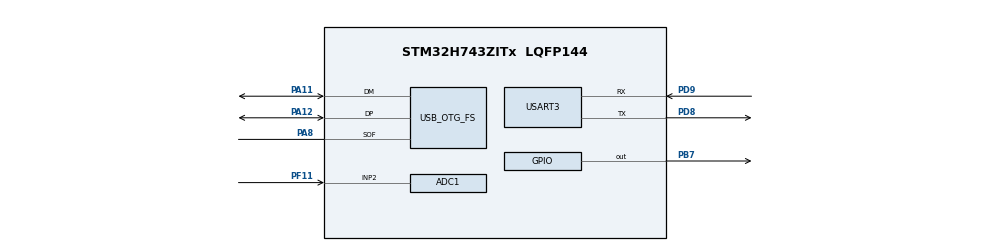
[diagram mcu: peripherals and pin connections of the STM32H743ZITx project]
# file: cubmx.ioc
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ADC1.Channel-0\#ChannelRegularConversion=ADC_CHANNEL_2
ADC1.NbrOfConversionFlag=1
ADC1.OffsetNumber-0\#ChannelRegularConversion=ADC_OFFSET_NONE
ADC1.Rank-0\#ChannelRegularConversion=1
ADC1.SamplingTime-0\#ChannelRegularConversion=ADC_SAMPLETIME_1CYCLE_5
ADC1.master=1
CORTEX_M7.CPU_DCache=Enabled
CORTEX_M7.CPU_ICache=Enabled
Dma.ADC1.0.Direction=DMA_PERIPH_TO_MEMORY
Dma.ADC1.0.EventEnable=DISABLE
Dma.ADC1.0.FIFOMode=DMA_FIFOMODE_ENABLE
Dma.ADC1.0.FIFOThreshold=DMA_FIFO_THRESHOLD_FULL
Dma.ADC1.0.Instance=DMA1_Stream0
Dma.ADC1.0.MemBurst=DMA_MBURST_SINGLE
Dma.ADC1.0.MemDataAlignment=DMA_MDATAALIGN_HALFWORD
Dma.ADC1.0.MemInc=DMA_MINC_ENABLE
Dma.ADC1.0.Mode=DMA_CIRCULAR
Dma.ADC1.0.PeriphBurst=DMA_PBURST_SINGLE
Dma.ADC1.0.PeriphDataAlignment=DMA_PDATAALIGN_HALFWORD
Dma.ADC1.0.PeriphInc=DMA_PINC_DISABLE
Dma.ADC1.0.Polarity=HAL_DMAMUX_REQ_GEN_RISING
Dma.ADC1.0.Priority=DMA_PRIORITY_LOW
Dma.ADC1.0.RequestNumber=1
Dma.ADC1.0.SyncEnable=ENABLE
Dma.ADC1.0.SyncPolarity=HAL_DMAMUX_SYNC_RISING
Dma.ADC1.0.SyncRequestNumber=1
Dma.Request0=ADC1
Mcu.Family=STM32H7
Mcu.Name=STM32H743ZITx
Mcu.Package=LQFP144
NVIC.DMA1_Stream0_IRQn=true\:0\:0\:false\:false\:true\:false
NVIC.DMAMUX1_OVR_IRQn=true\:0\:0\:false\:false\:true\:false
NVIC.OTG_FS_IRQn=true\:0\:0\:false\:false\:true\:false
NVIC.PriorityGroup=NVIC_PRIORITYGROUP_4
PA11.Mode=Device_Only
PA11.Signal=USB_OTG_FS_DM
PA12.Mode=Device_Only
PA12.Signal=USB_OTG_FS_DP
PA13\ (JTMS/SWDIO).Mode=Serial_Wire
PA13\ (JTMS/SWDIO).Signal=SYS_JTMS-SWDIO
PA14\ (JTCK/SWCLK).Mode=Serial_Wire
PA14\ (JTCK/SWCLK).Signal=SYS_JTCK-SWCLK
PA8.Mode=Activate_SOF_FS
PA8.Signal=USB_OTG_FS_SOF
PB7.Signal=GPIO_Output
PD8.Mode=Asynchronous
PD8.Signal=USART3_TX
PD9.Mode=Asynchronous
PD9.Signal=USART3_RX
PF11.Mode=IN2-Single-Ended
PF11.Signal=ADC1_INP2
PH0-OSC_IN\ (PH0).Mode=HSE-External-Clock-Source
PH0-OSC_IN\ (PH0).Signal=RCC_OSC_IN
PH1-OSC_OUT\ (PH1).Mode=HSE-External-Clock-Source
PH1-OSC_OUT\ (PH1).Signal=RCC_OSC_OUT
ProjectManager.HeapSize=0x200
ProjectManager.StackSize=0x800
ProjectManager.TargetToolchain=Makefile
RCC.ADCCLockSelection=RCC_ADCCLKSOURCE_CLKP
RCC.ADCFreq_Value=64000000
RCC.APB1Freq_Value=100000000
RCC.APB2Freq_Value=100000000
RCC.APB3Freq_Value=100000000
RCC.APB4Freq_Value=100000000
RCC.CortexFreq_Value=400000000
RCC.D1PPRE=RCC_APB3_DIV2
RCC.D2PPRE1=RCC_APB1_DIV2
RCC.D2PPRE2=RCC_APB2_DIV2
RCC.D3PPRE=RCC_APB4_DIV2
RCC.DIVM1=1
RCC.DIVN1=100
RCC.DIVQ1=4
RCC.HCLKFreq_Value=200000000
RCC.HPRE=RCC_HCLK_DIV2
RCC.HSE_VALUE=8000000
RCC.PLLSourceVirtual=RCC_PLLSOURCE_HSE
RCC.SYSCLKFreq_VALUE=400000000
RCC.SYSCLKSource=RCC_SYSCLKSOURCE_PLLCLK
RCC.USBCLockSelection=RCC_USBCLKSOURCE_HSI48
RCC.USBFreq_Value=48000000
USART3.VirtualMode-Asynchronous=VM_ASYNC
USB_DEVICE.CLASS_NAME_FS=CDC
USB_DEVICE.VirtualMode-CDC_FS=Cdc
USB_DEVICE.VirtualModeFS=Cdc_FS
USB_OTG_FS.VirtualMode=Device_Only
USB_OTG_FS.battery_charging_enable=DISABLE
VP_USB_DEVICE_VS_USB_DEVICE_CDC_FS.Mode=CDC_FS
board=custom

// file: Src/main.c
/* USER CODE BEGIN Header */
/**
  ******************************************************************************
  * @file           : main.c
  * @brief          : Main program body
  ******************************************************************************
  ** This notice applies to any and all portions of this file
  * that are not between comment pairs USER CODE BEGIN and
  * USER CODE END. Other portions of this file, whether
  * inserted by the user or by software development tools
  * are owned by their respective copyright owners.
  *
  * COPYRIGHT(c) 2019 STMicroelectronics
  *
  * Redistribution and use in source and binary forms, with or without modification,
  * are permitted provided that the following conditions are met:
  *   1. Redistributions of source code must retain the above copyright notice,
  *      this list of conditions and the following disclaimer.
  *   2. Redistributions in binary form must reproduce the above copyright notice,
  *      this list of conditions and the following disclaimer in the documentation
  *      and/or other materials provided with the distribution.
  *   3. Neither the name of STMicroelectronics nor the names of its contributors
  *      may be used to endorse or promote products derived from this software
  *      without specific prior written permission.
  *
  * THIS SOFTWARE IS PROVIDED BY THE COPYRIGHT HOLDERS AND CONTRIBUTORS "AS IS"
  * AND ANY EXPRESS OR IMPLIED WARRANTIES, INCLUDING, BUT NOT LIMITED TO, THE
  * IMPLIED WARRANTIES OF MERCHANTABILITY AND FITNESS FOR A PARTICULAR PURPOSE ARE
  * DISCLAIMED. IN NO EVENT SHALL THE COPYRIGHT HOLDER OR CONTRIBUTORS BE LIABLE
  * FOR ANY DIRECT, INDIRECT, INCIDENTAL, SPECIAL, EXEMPLARY, OR CONSEQUENTIAL
  * DAMAGES (INCLUDING, BUT NOT LIMITED TO, PROCUREMENT OF SUBSTITUTE GOODS OR
  * SERVICES; LOSS OF USE, DATA, OR PROFITS; OR BUSINESS INTERRUPTION) HOWEVER
  * CAUSED AND ON ANY THEORY OF LIABILITY, WHETHER IN CONTRACT, STRICT LIABILITY,
  * OR TORT (INCLUDING NEGLIGENCE OR OTHERWISE) ARISING IN ANY WAY OUT OF THE USE
  * OF THIS SOFTWARE, EVEN IF ADVISED OF THE POSSIBILITY OF SUCH DAMAGE.
  *
  ******************************************************************************
  */
/* USER CODE END Header */

#include "main.h"
#include "usb_device.h"

ADC_HandleTypeDef hadc1;
DMA_HandleTypeDef hdma_adc1;

UART_HandleTypeDef huart3;

/* USER CODE BEGIN PV */
  extern void hwInit();
  extern void apInit();

  extern void apMain();

/* USER CODE END PV */

void SystemClock_Config(void);
static void MX_GPIO_Init(void);
static void MX_DMA_Init(void);
static void MX_USART3_UART_Init(void);
static void MX_ADC1_Init(void);

int main(void)
{

  /* Enable I-Cache---------------------------------------------------------*/
  SCB_EnableICache();

  /* Enable D-Cache---------------------------------------------------------*/
  SCB_EnableDCache();

  /* MCU Configuration--------------------------------------------------------*/

  /* Reset of all peripherals, Initializes the Flash interface and the Systick. */
  HAL_Init();

  /* Configure the system clock */
  SystemClock_Config();

  /* Initialize all configured peripherals */
  MX_GPIO_Init();
  MX_DMA_Init();
  MX_USB_DEVICE_Init();
  MX_USART3_UART_Init();
  MX_ADC1_Init();
  /* USER CODE BEGIN 2 */

  hwInit();
  apInit();

  apMain();
  /* USER CODE END 2 */

  /* Infinite loop */
  while (1)
  {

  }
}

void SystemClock_Config(void)
{
  RCC_OscInitTypeDef RCC_OscInitStruct = {0};
  RCC_ClkInitTypeDef RCC_ClkInitStruct = {0};
  RCC_PeriphCLKInitTypeDef PeriphClkInitStruct = {0};

  /**Supply configuration update enable
  */
  MODIFY_REG(PWR->CR3, PWR_CR3_SCUEN, 0);
  /**Configure the main internal regulator output voltage
  */
  __HAL_PWR_VOLTAGESCALING_CONFIG(PWR_REGULATOR_VOLTAGE_SCALE1);

  while ((PWR->D3CR & (PWR_D3CR_VOSRDY)) != PWR_D3CR_VOSRDY)
  {

  }
  /**Initializes the CPU, AHB and APB busses clocks
  */
  RCC_OscInitStruct.OscillatorType = RCC_OSCILLATORTYPE_HSI48|RCC_OSCILLATORTYPE_HSI
                              |RCC_OSCILLATORTYPE_HSE;
  RCC_OscInitStruct.HSEState = RCC_HSE_BYPASS;
  RCC_OscInitStruct.HSIState = RCC_HSI_DIV1;
  RCC_OscInitStruct.HSICalibrationValue = RCC_HSICALIBRATION_DEFAULT;
  RCC_OscInitStruct.HSI48State = RCC_HSI48_ON;
  RCC_OscInitStruct.PLL.PLLState = RCC_PLL_ON;
  RCC_OscInitStruct.PLL.PLLSource = RCC_PLLSOURCE_HSE;
  RCC_OscInitStruct.PLL.PLLM = 1;
  RCC_OscInitStruct.PLL.PLLN = 100;
  RCC_OscInitStruct.PLL.PLLP = 2;
  RCC_OscInitStruct.PLL.PLLQ = 4;
  RCC_OscInitStruct.PLL.PLLR = 2;
  RCC_OscInitStruct.PLL.PLLRGE = RCC_PLL1VCIRANGE_3;
  RCC_OscInitStruct.PLL.PLLVCOSEL = RCC_PLL1VCOWIDE;
  RCC_OscInitStruct.PLL.PLLFRACN = 0;
  if (HAL_RCC_OscConfig(&RCC_OscInitStruct) != HAL_OK)
  {
    Error_Handler();
  }
  /**Initializes the CPU, AHB and APB busses clocks
  */
  RCC_ClkInitStruct.ClockType = RCC_CLOCKTYPE_HCLK|RCC_CLOCKTYPE_SYSCLK
                              |RCC_CLOCKTYPE_PCLK1|RCC_CLOCKTYPE_PCLK2
                              |RCC_CLOCKTYPE_D3PCLK1|RCC_CLOCKTYPE_D1PCLK1;
  RCC_ClkInitStruct.SYSCLKSource = RCC_SYSCLKSOURCE_PLLCLK;
  RCC_ClkInitStruct.SYSCLKDivider = RCC_SYSCLK_DIV1;
  RCC_ClkInitStruct.AHBCLKDivider = RCC_HCLK_DIV2;
  RCC_ClkInitStruct.APB3CLKDivider = RCC_APB3_DIV2;
  RCC_ClkInitStruct.APB1CLKDivider = RCC_APB1_DIV2;
  RCC_ClkInitStruct.APB2CLKDivider = RCC_APB2_DIV2;
  RCC_ClkInitStruct.APB4CLKDivider = RCC_APB4_DIV2;

  if (HAL_RCC_ClockConfig(&RCC_ClkInitStruct, FLASH_LATENCY_2) != HAL_OK)
  {
    Error_Handler();
  }
  PeriphClkInitStruct.PeriphClockSelection = RCC_PERIPHCLK_USART3|RCC_PERIPHCLK_ADC
                              |RCC_PERIPHCLK_USB|RCC_PERIPHCLK_CKPER;
  PeriphClkInitStruct.CkperClockSelection = RCC_CLKPSOURCE_HSI;
  PeriphClkInitStruct.Usart234578ClockSelection = RCC_USART234578CLKSOURCE_D2PCLK1;
  PeriphClkInitStruct.UsbClockSelection = RCC_USBCLKSOURCE_HSI48;
  PeriphClkInitStruct.AdcClockSelection = RCC_ADCCLKSOURCE_CLKP;
  if (HAL_RCCEx_PeriphCLKConfig(&PeriphClkInitStruct) != HAL_OK)
  {
    Error_Handler();
  }
}

static void MX_ADC1_Init(void)
{

  ADC_MultiModeTypeDef multimode = {0};
  ADC_ChannelConfTypeDef sConfig = {0};

  /**Common config
  */
  hadc1.Instance = ADC1;
  hadc1.Init.ClockPrescaler = ADC_CLOCK_ASYNC_DIV2;
  hadc1.Init.Resolution = ADC_RESOLUTION_16B;
  hadc1.Init.ScanConvMode = ADC_SCAN_DISABLE;
  hadc1.Init.EOCSelection = ADC_EOC_SINGLE_CONV;
  hadc1.Init.LowPowerAutoWait = DISABLE;
  hadc1.Init.ContinuousConvMode = DISABLE;
  hadc1.Init.NbrOfConversion = 1;
  hadc1.Init.DiscontinuousConvMode = DISABLE;
  hadc1.Init.ExternalTrigConv = ADC_SOFTWARE_START;
  hadc1.Init.ExternalTrigConvEdge = ADC_EXTERNALTRIGCONVEDGE_NONE;
  hadc1.Init.ConversionDataManagement = ADC_CONVERSIONDATA_DR;
  hadc1.Init.Overrun = ADC_OVR_DATA_PRESERVED;
  hadc1.Init.LeftBitShift = ADC_LEFTBITSHIFT_NONE;
  hadc1.Init.BoostMode = DISABLE;
  hadc1.Init.OversamplingMode = DISABLE;
  if (HAL_ADC_Init(&hadc1) != HAL_OK)
  {
    Error_Handler();
  }
  /**Configure the ADC multi-mode
  */
  multimode.Mode = ADC_MODE_INDEPENDENT;
  if (HAL_ADCEx_MultiModeConfigChannel(&hadc1, &multimode) != HAL_OK)
  {
    Error_Handler();
  }
  /**Configure Regular Channel
  */
  sConfig.Channel = ADC_CHANNEL_2;
  sConfig.Rank = ADC_REGULAR_RANK_1;
  sConfig.SamplingTime = ADC_SAMPLETIME_1CYCLE_5;
  sConfig.SingleDiff = ADC_SINGLE_ENDED;
  sConfig.OffsetNumber = ADC_OFFSET_NONE;
  sConfig.Offset = 0;
  if (HAL_ADC_ConfigChannel(&hadc1, &sConfig) != HAL_OK)
  {
    Error_Handler();
  }

}

static void MX_USART3_UART_Init(void)
{

  huart3.Instance = USART3;
  huart3.Init.BaudRate = 115200;
  huart3.Init.WordLength = UART_WORDLENGTH_8B;
  huart3.Init.StopBits = UART_STOPBITS_1;
  huart3.Init.Parity = UART_PARITY_NONE;
  huart3.Init.Mode = UART_MODE_TX_RX;
  huart3.Init.HwFlowCtl = UART_HWCONTROL_NONE;
  huart3.Init.OverSampling = UART_OVERSAMPLING_16;
  huart3.Init.OneBitSampling = UART_ONE_BIT_SAMPLE_DISABLE;
  huart3.Init.Prescaler = UART_PRESCALER_DIV1;
  huart3.Init.FIFOMode = UART_FIFOMODE_DISABLE;
  huart3.Init.TXFIFOThreshold = UART_TXFIFO_THRESHOLD_1_8;
  huart3.Init.RXFIFOThreshold = UART_RXFIFO_THRESHOLD_1_8;
  huart3.AdvancedInit.AdvFeatureInit = UART_ADVFEATURE_NO_INIT;
  if (HAL_UART_Init(&huart3) != HAL_OK)
  {
    Error_Handler();
  }

}

static void MX_DMA_Init(void)
{
  /* DMA controller clock enable */
  __HAL_RCC_DMA1_CLK_ENABLE();

  /* DMA interrupt init */
  /* DMA1_Stream0_IRQn interrupt configuration */
  HAL_NVIC_SetPriority(DMA1_Stream0_IRQn, 0, 0);
  HAL_NVIC_EnableIRQ(DMA1_Stream0_IRQn);

}

static void MX_GPIO_Init(void)
{
  GPIO_InitTypeDef GPIO_InitStruct = {0};

  /* GPIO Ports Clock Enable */
  __HAL_RCC_GPIOH_CLK_ENABLE();
  __HAL_RCC_GPIOF_CLK_ENABLE();
  __HAL_RCC_GPIOD_CLK_ENABLE();
  __HAL_RCC_GPIOA_CLK_ENABLE();
  __HAL_RCC_GPIOB_CLK_ENABLE();

  /*Configure GPIO pin Output Level */
  HAL_GPIO_WritePin(GPIOB, GPIO_PIN_7, GPIO_PIN_RESET);

  /*Configure GPIO pin : PB7 */
  GPIO_InitStruct.Pin = GPIO_PIN_7;
  GPIO_InitStruct.Mode = GPIO_MODE_OUTPUT_PP;
  GPIO_InitStruct.Pull = GPIO_NOPULL;
  GPIO_InitStruct.Speed = GPIO_SPEED_FREQ_LOW;
  HAL_GPIO_Init(GPIOB, &GPIO_InitStruct);

}

void Error_Handler(void)
{
}

/************************ (C) COPYRIGHT STMicroelectronics *****END OF FILE****/
